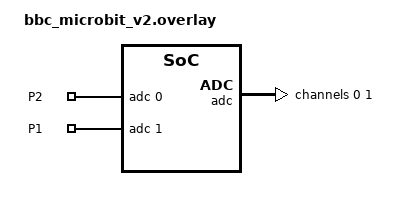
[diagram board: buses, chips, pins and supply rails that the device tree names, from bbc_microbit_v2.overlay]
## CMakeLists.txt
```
cmake_minimum_required(VERSION 3.20.0)
find_package(Zephyr REQUIRED HINTS $ENV{ZEPHYR_BASE})

project(Bit_Player_micro_bit)

target_sources(app PRIVATE 
    src/main.c
    src/joystick_state.c
    src/sender_ble.c
)
```

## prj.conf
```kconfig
# Sender prj.conf - State-based
# Zephyr SDK v2.5.1

CONFIG_SERIAL=y
CONFIG_CONSOLE=y
CONFIG_UART_CONSOLE=y
CONFIG_PRINTK=y

# ADC for joystick
CONFIG_ADC=y
CONFIG_ADC_NRFX_SAADC=y
CONFIG_ADC_ASYNC=y

# GPIO for buttons
CONFIG_GPIO=y

# System
CONFIG_SYSTEM_WORKQUEUE_STACK_SIZE=2048
CONFIG_MAIN_STACK_SIZE=2048
CONFIG_HEAP_MEM_POOL_SIZE=4096

# Bluetooth - Peripheral (sender advertiser)
CONFIG_BT=y
CONFIG_BT_PERIPHERAL=y
CONFIG_BT_DEVICE_NAME="BitPlayer_Joy"
CONFIG_BT_MAX_CONN=1
CONFIG_BT_GATT_DYNAMIC_DB=y

# Buffer
CONFIG_BT_L2CAP_TX_BUF_COUNT=8
CONFIG_BT_L2CAP_TX_MTU=65
CONFIG_BT_BUF_ACL_TX_SIZE=27
CONFIG_BT_BUF_ACL_RX_SIZE=70
```

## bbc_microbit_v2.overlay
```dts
/ {
	zephyr,user {
		io-channels = <&adc 0>, <&adc 1>;
		io-channel-names = "P2", "P1";
	};
};

&adc {
	#address-cells = <1>;
	#size-cells = <0>;
	status = "okay";

	channel@0 {
		reg = <0>;
		zephyr,gain = "ADC_GAIN_1_5";
		zephyr,reference = "ADC_REF_INTERNAL";
		zephyr,acquisition-time = <ADC_ACQ_TIME_DEFAULT>;
		zephyr,input-positive = <2>;  /* AIN2 = P0.04 = P2 edge */
		zephyr,resolution = <10>;
	};

	channel@1 {
		reg = <1>;
		zephyr,gain = "ADC_GAIN_1_5";
		zephyr,reference = "ADC_REF_INTERNAL";
		zephyr,acquisition-time = <ADC_ACQ_TIME_DEFAULT>;
		zephyr,input-positive = <1>;  /* AIN1 = P0.03 = P1 edge */
		zephyr,resolution = <10>;
	};
};
```

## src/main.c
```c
#include <zephyr/kernel.h>
#include <zephyr/device.h>
#include <zephyr/devicetree.h>
#include <zephyr/drivers/adc.h>
#include <zephyr/drivers/gpio.h>
#include <zephyr/sys/printk.h>
#include <nrfx_saadc.h>

#include "joystick_state.h"
#include "sender_ble.h"
#include "motor_types.h"

#define ADC_NODE DT_NODELABEL(adc)
#define RESOLUTION 10 

#define SEND_INTERVAL_MS 100
#define POLL_INTERVAL_MS 20

static const struct gpio_dt_spec btn_a = GPIO_DT_SPEC_GET(DT_ALIAS(sw0), gpios);
static const struct gpio_dt_spec btn_b = GPIO_DT_SPEC_GET(DT_ALIAS(sw1), gpios);

static const struct device *adc_dev;
static int16_t adc_buffer[1];
static int16_t last_x = 512, last_y = 512; 
static int64_t last_send = 0; 

// Configuration for Y axis
static struct adc_channel_cfg cfg_y = {
    .gain = ADC_GAIN_1_5,
    .reference = ADC_REF_INTERNAL,
    .acquisition_time = ADC_ACQ_TIME_DEFAULT,
    .channel_id = 0,
#ifdef CONFIG_ADC_NRFX_SAADC
    .input_positive = NRF_SAADC_INPUT_AIN2,
#endif
};

// Configuration for X axis
static struct adc_channel_cfg cfg_x = {
    .gain = ADC_GAIN_1_5,                   //3,0 V
    .reference = ADC_REF_INTERNAL,
    .acquisition_time = ADC_ACQ_TIME_DEFAULT,
    .channel_id = 1,
#ifdef CONFIG_ADC_NRFX_SAADC
    .input_positive = NRF_SAADC_INPUT_AIN1,
#endif
};

// Read ADC value from specified channel
static int read_adc(int ch, int16_t *val)
{
    struct adc_sequence seq = {
        .buffer = adc_buffer,               // Buffer to store ADC value    
        .buffer_size = sizeof(adc_buffer),  // Buffer size in bytes
        .resolution = RESOLUTION,           // 10-bit resolution
        .channels = BIT(ch),                
    };
    // Perform the ADC read
    int ret = adc_read(adc_dev, &seq);
    if (ret < 0) return ret;
    *val = (adc_buffer[0] < 0) ? 0 : (adc_buffer[0] > 1023) ? 1023 : adc_buffer[0];
    return 0;
}

// Helper to get string name of direction
static const char *dir_name(Motor_direction d)
{
    switch (d) {
        case Forward: return "FWD";
        case Backward: return "BWD";
        case Rotate_Right: return "ROT_R";
        case Rotate_Left: return "ROT_L";
        case Right: return "RIGHT";
        case Left: return "LEFT";
        case Stop: return "STOP";
        case Idle: return "IDLE";
        default: return "?";
    }
}

int main(void)
{
    int16_t y, x;
    Motor_direction dir; // Current direction
    uint8_t speed;

    printk("\n=== Joystick Sender (DEBUG) ===\n");
    printk("Sends Motor_direction directly\n\n");

    if (device_is_ready(btn_a.port)) {
        gpio_pin_configure_dt(&btn_a, GPIO_INPUT | GPIO_PULL_UP); // Configure button A
        gpio_pin_configure_dt(&btn_b, GPIO_INPUT | GPIO_PULL_UP); // Configure button B
    }

    adc_dev = DEVICE_DT_GET(ADC_NODE);
    if (!device_is_ready(adc_dev)) {
        printk("ADC not ready\n");
        return -1;
    }
    adc_channel_setup(adc_dev, &cfg_y);
    adc_channel_setup(adc_dev, &cfg_x);

    joystick_state_init();  // Initialize joystick state
    ble_init();             // Initialize BLE   
    ble_connect();          // Wait until BLE is ready

    printk("Hold A to drive\n\n");

    while (1) {
        // Read joystick
        if (read_adc(cfg_y.channel_id, &y) < 0) y = last_y;
        else last_y = y;

        if (read_adc(cfg_x.channel_id, &x) < 0) x = last_x;
        else last_x = x;

        bool btn = (gpio_pin_get_dt(&btn_a) != 0);
        bool btn_b_state = (gpio_pin_get_dt(&btn_b) != 0);

        // Convert to direction
        bool changed = joystick_to_direction(x, y, btn, btn_b_state, &dir, &speed);

        // DEBUG: Always print raw values 
        printk("X:%4d Y:%4d btn:%d -> %-5s %3d%%", x, y, btn ? 1 : 0, dir_name(dir), speed);

        // Send if changed or interval passed 
        int64_t now = k_uptime_get();
        if (ble_is_ready() && (changed || (now - last_send) >= SEND_INTERVAL_MS)) {
            ble_send_direction(dir, speed);
            last_send = now;
            printk(" [TX]");
        }
        printk("\n");

        k_msleep(POLL_INTERVAL_MS); // Polling interval
    }
    return 0;
}
```

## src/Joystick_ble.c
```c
//Joystick_ble.c - SIMPLIFIED VERSION

#include <zephyr/kernel.h>
#include <zephyr/sys/printk.h>
#include <string.h>

#include <zephyr/bluetooth/bluetooth.h>
#include <zephyr/bluetooth/uuid.h>
#include <zephyr/bluetooth/conn.h>
#include <zephyr/bluetooth/gatt.h>

#include "joystick_ble.h"

#define JOYSTICK_SVC_UUID \
	BT_UUID_128_ENCODE(0x12345678, 0x1234, 0x5678, 0x1234, 0x56789abcdef0)
#define JOYSTICK_CHR_UUID \
	BT_UUID_128_ENCODE(0x12345678, 0x1234, 0x5678, 0x1234, 0x56789abcdef1)

static struct bt_uuid_128 joystick_svc_uuid = BT_UUID_INIT_128(JOYSTICK_SVC_UUID);
static struct bt_uuid_128 joystick_chr_uuid = BT_UUID_INIT_128(JOYSTICK_CHR_UUID);

static const struct bt_data ad[] = {
	BT_DATA_BYTES(BT_DATA_FLAGS, (BT_LE_AD_GENERAL | BT_LE_AD_NO_BREDR)),
	BT_DATA_BYTES(BT_DATA_UUID128_ALL, JOYSTICK_SVC_UUID),
};

static struct bt_conn *default_conn;
static const struct bt_gatt_attr *local_attr;
static bool remote_ready;
static bool is_connected;

/* Joystick data */
struct joystick_data {
	int16_t x_pos;
	int16_t y_pos;
	uint8_t buttons;
} __packed;

/* Send data - enkel versjon */
void ble_send_joystick_data(int16_t x_pos, int16_t y_pos, uint8_t buttons)
{
	if (!default_conn || !remote_ready) return;

	struct joystick_data data = {
		.x_pos = x_pos,
		.y_pos = y_pos,
		.buttons = buttons,
	};

	int err = bt_gatt_notify(default_conn, local_attr, &data, sizeof(data));
	if (err && err != -ENOMEM && err != -ENOTCONN) {
		printk("Notify err %d\n", err);
	}
}

bool ble_is_ready(void)
{
	return (default_conn != NULL && remote_ready);
}

static void joystick_ccc_cfg_changed(const struct bt_gatt_attr *attr, uint16_t val)
{
	remote_ready = (val == BT_GATT_CCC_NOTIFY);
	printk("CCC: %s\n", remote_ready ? "subscribed" : "unsubscribed");
}

BT_GATT_SERVICE_DEFINE(joystick_svc,
	BT_GATT_PRIMARY_SERVICE(&joystick_svc_uuid.uuid),
	BT_GATT_CHARACTERISTIC(&joystick_chr_uuid.uuid, 
	                       BT_GATT_CHRC_NOTIFY,
	                       BT_GATT_PERM_NONE, 
	                       NULL, NULL, NULL),
	BT_GATT_CCC(joystick_ccc_cfg_changed,
	            BT_GATT_PERM_READ | BT_GATT_PERM_WRITE),
);

/* Auto-reconnect work */
static void restart_adv_work(struct k_work *work);
K_WORK_DELAYABLE_DEFINE(adv_work, restart_adv_work);

static void restart_adv_work(struct k_work *work)
{
	if (!is_connected) {
		int err = bt_le_adv_start(BT_LE_ADV_CONN_NAME, ad, ARRAY_SIZE(ad), NULL, 0);
		if (err && err != -EALREADY) {
			printk("Adv retry in 1s\n");
			k_work_schedule(&adv_work, K_SECONDS(1));
		} else {
			printk("Advertising...\n");
		}
	}
}

static void connected(struct bt_conn *conn, uint8_t err)
{
	if (err) {
		printk("Connect failed: 0x%02x\n", err);
		k_work_schedule(&adv_work, K_MSEC(200));
		return;
	}

	printk("Connected\n");
	if (!default_conn) {
		default_conn = bt_conn_ref(conn);
	}
	is_connected = true;
	remote_ready = false;
}

static void disconnected(struct bt_conn *conn, uint8_t reason)
{
	printk("Disconnected: 0x%02x\n", reason);

	if (default_conn) {
		bt_conn_unref(default_conn);
		default_conn = NULL;
	}
	is_connected = false;
	remote_ready = false;

	/* Rask reconnect */
	k_work_schedule(&adv_work, K_MSEC(100));
}

static struct bt_conn_cb conn_callbacks = {
	.connected = connected,
	.disconnected = disconnected,
};

void ble_connect(void)
{
	if (is_connected) return;

	int err = bt_le_adv_start(BT_LE_ADV_CONN_NAME, ad, ARRAY_SIZE(ad), NULL, 0);
	if (err) {
		printk("Adv failed: %d\n", err);
		k_work_schedule(&adv_work, K_MSEC(500));
		return;
	}
	printk("Advertising started\n");
}

void ble_cancel_connect(void)
{
	k_work_cancel_delayable(&adv_work);
	if (is_connected && default_conn) {
		bt_conn_disconnect(default_conn, BT_HCI_ERR_REMOTE_USER_TERM_CONN);
	} else {
		bt_le_adv_stop();
	}
}

void ble_init(void)
{
	int err = bt_enable(NULL);
	if (err) {
		printk("BT init failed: %d\n", err);
		return;
	}
	printk("Bluetooth ready\n");
	bt_conn_cb_register(&conn_callbacks);
	local_attr = &joystick_svc.attrs[1];
}
```

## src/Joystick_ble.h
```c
#ifndef JOYSTICK_BLE_H
#define JOYSTICK_BLE_H

#include <stdbool.h>
#include <stdint.h>

#define BTN_A_MASK (1 << 0)
#define BTN_B_MASK (1 << 1)

void ble_init(void);
void ble_connect(void);
void ble_cancel_connect(void);
void ble_send_joystick_data(int16_t x_pos, int16_t y_pos, uint8_t buttons);
bool ble_is_ready(void);

#endif
```

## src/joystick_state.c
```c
#include "joystick_state.h"

#define JOY_CENTER 512
#define JOY_DEADZONE 60
#define JOY_MAX 1023

static Motor_direction current_dir = Stop;

void joystick_state_init(void) {
	current_dir = Stop;
}

// Convert joystick position and button states to motor direction and speed
bool joystick_to_direction(int16_t x_pos, int16_t y_pos, bool btn_a, bool btn_b, Motor_direction *dir, uint8_t *speed) {

	Motor_direction new_dir = Stop; 
	int8_t new_speed = 0;

	if (!btn_a){
		new_dir = Idle;
		new_speed = 0;
		goto done;
	}

	// Calculate forward/backward and turning components
	int32_t fwd = 0;
	if (y_pos > JOY_CENTER + JOY_DEADZONE) {
		fwd = ((y_pos - JOY_CENTER) * 100) / (JOY_MAX - JOY_CENTER);
	} else if (y_pos < JOY_CENTER - JOY_DEADZONE) {
		fwd = -((JOY_CENTER - y_pos) * 100) / (JOY_CENTER);
	}

	// Calculate turning component
	int32_t turn = 0;
	if (x_pos > JOY_CENTER + JOY_DEADZONE) {
		turn = ((x_pos - JOY_CENTER) * 100) / (JOY_MAX - JOY_CENTER);
	} else if (x_pos < JOY_CENTER - JOY_DEADZONE) {
		turn = -((JOY_CENTER - x_pos) * 100) / (JOY_CENTER);
	}
	
	// Determine direction and speed
	if (fwd == 0 && turn == 0) {
		new_dir = Stop;
		new_speed = 0;
		goto done;
	}

	// Determine speed based on the larger of forward or turning component
    int32_t abs_fwd = (fwd >= 0) ? fwd : -fwd;
    int32_t abs_turn = (turn >= 0) ? turn : -turn;

	new_speed = (abs_fwd > abs_turn) ? abs_fwd : abs_turn;
	if (new_speed > 100) new_speed = 100;

	if(abs_fwd < 25 && abs_turn > 10){
		if (btn_b) {
			// Knapp B: Strafe (sideveis)
			new_dir = (turn > 0) ? Right : Left;
		} else {
			// Normal: Roter på stedet
			new_dir = (turn > 0) ? Rotate_Right : Rotate_Left;
		}
		goto done;
	}

	// Forward/backward with possible slight turn
	if (fwd > 0) {
		if (abs_turn > 50)
			new_dir = (turn > 0) ? Right : Left;
		else {
			new_dir = Forward;
		}
	} else if (fwd < 0) {
		if (abs_turn > 50)
			new_dir = (turn > 0) ? Right : Left;
		else {
			new_dir = Backward;
		}
	} else {
		if (abs_turn > 10) {
            new_dir = (turn > 0) ? Rotate_Right : Rotate_Left;
        }
	}

done:
 *dir = new_dir;
 *speed = new_speed;

 bool changed = (new_dir != current_dir);
 current_dir = new_dir;
 return changed;
}
```

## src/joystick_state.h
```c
#ifndef JOYSTICK_STATE_H
#define JOYSTICK_STATE_H

#include "motor_types.h"
#include <stdbool.h>

void joystick_state_init(void);

bool joystick_to_direction(int16_t x_pos, int16_t y_pos, bool btn_a_pressed, bool btn_b_pressed, Motor_direction *dir, uint8_t *speed);

#endif
```

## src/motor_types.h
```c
/*
* Acknowledgement:
* This file includes example code derrived from https://github.com/OskeLTU
* Driving_car motor_controls.h
*/

#ifndef MOTOR_TYPES_H
#define MOTOR_TYPES_H
#include <stdint.h>
typedef enum {
    Forward,
    Backward,
    Rotate_Right,
    Rotate_Left,
    Right,
    Left,
    Stop,
    Idle
} Motor_direction;

struct drive_packet {
    uint8_t direction;  // Motor_direction
    uint8_t speed;      // Speed value 0-100%
} __packed;
 #endif // MOTOR_TYPES_H
```

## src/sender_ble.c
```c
/*
* Acknowledgement:
* This file includes example code derrived from the Zephyr Project 
* Pong sample
*/
#include <zephyr/kernel.h>
#include <zephyr/sys/printk.h>
#include <zephyr/bluetooth/bluetooth.h>
#include <zephyr/bluetooth/uuid.h>
#include <zephyr/bluetooth/conn.h>
#include <zephyr/bluetooth/gatt.h>

#include "sender_ble.h"
#include "motor_types.h"

// UUIDs for the Drive Service and Characteristic
#define DRIVE_SVC_UUID \
    BT_UUID_128_ENCODE(0x12345678, 0x1234, 0x5678, 0x1234, 0x56789abcdef0)

// Characteristic UUID
#define DRIVE_CHR_UUID \
    BT_UUID_128_ENCODE(0x12345678, 0x1234, 0x5678, 0x1234, 0x56789abcdef1)

static struct bt_uuid_128 svc_uuid = BT_UUID_INIT_128(DRIVE_SVC_UUID); // Service UUID
static struct bt_uuid_128 chr_uuid = BT_UUID_INIT_128(DRIVE_CHR_UUID); // Characteristic UUID

// Advertising data
static const struct bt_data ad[] = {
    BT_DATA_BYTES(BT_DATA_FLAGS, (BT_LE_AD_GENERAL | BT_LE_AD_NO_BREDR)),
    BT_DATA_BYTES(BT_DATA_UUID128_ALL, DRIVE_SVC_UUID),
};

// Connection state
static struct bt_conn *conn;                    // Current connection
static const struct bt_gatt_attr *notify_attr;  // Notify characteristic attribute
static bool subscribed;                         // Is client subscribed to notifications
static bool connected;                          // Is device connected

// GATT characteristic write callback
void ble_send_direction(Motor_direction dir, uint8_t speed) {
    if (!connected || !subscribed) {
        return;
    }

    struct drive_packet packet = {
        .direction = (uint8_t)dir,
        .speed = speed
    };

    bt_gatt_notify(conn, notify_attr, &packet, sizeof(packet));
}

// Bluetooth connection callbacks
bool ble_is_ready(void) {
    return (conn != NULL && subscribed);
}

// Bluetooth connection callbacks
static void ccc_changed(const struct bt_gatt_attr *attr, uint16_t val)
{
    subscribed = (val == BT_GATT_CCC_NOTIFY);
    printk("Subscribed: %s\n", subscribed ? "yes" : "no");
}

// GATT service definition
BT_GATT_SERVICE_DEFINE(drive_svc,
    BT_GATT_PRIMARY_SERVICE(&svc_uuid.uuid),
    BT_GATT_CHARACTERISTIC(&chr_uuid.uuid,
                           BT_GATT_CHRC_NOTIFY,
                           BT_GATT_PERM_NONE,
                           NULL, NULL, NULL),
    BT_GATT_CCC(ccc_changed, BT_GATT_PERM_READ | BT_GATT_PERM_WRITE),
);

// Reconnection work item
static void reconnect_work_fn(struct k_work *work);
K_WORK_DELAYABLE_DEFINE(reconnect_work, reconnect_work_fn);

static void reconnect_work_fn(struct k_work *work)
{
    if (!connected) {
        int err = bt_le_adv_start(BT_LE_ADV_CONN_NAME, ad, ARRAY_SIZE(ad), NULL, 0);
        if (err && err != -EALREADY) {
            k_work_schedule(&reconnect_work, K_SECONDS(1));
        }
    }
}

// Connection callbacks
static void on_connected(struct bt_conn *c, uint8_t err)
{
    if (err) {
        printk("Connect failed: %d\n", err);
        k_work_schedule(&reconnect_work, K_MSEC(200));
        return;
    }
    printk("Connected\n");
    conn = bt_conn_ref(c);
    connected = true;
    subscribed = false;
}


// Disconnection callback
static void on_disconnected(struct bt_conn *c, uint8_t reason)
{
    printk("Disconnected: 0x%02x\n", reason);
    if (conn) {
        bt_conn_unref(conn);
        conn = NULL;
    }
    connected = false;
    subscribed = false;
    k_work_schedule(&reconnect_work, K_MSEC(100));
}

/* Connection callbacks */
static struct bt_conn_cb conn_cb = {
    .connected = on_connected,
    .disconnected = on_disconnected,
};

void ble_connect(void)
{
    if (connected) return;
    int err = bt_le_adv_start(BT_LE_ADV_CONN_NAME, ad, ARRAY_SIZE(ad), NULL, 0);
    if (err) {
        printk("Adv failed: %d\n", err);
        k_work_schedule(&reconnect_work, K_MSEC(500));
    } else {
        printk("Advertising...\n");
    }
}

void ble_init(void)
{
    int err = bt_enable(NULL);
    if (err) {
        printk("BT init failed: %d\n", err);
        return;
    }
    printk("Bluetooth ready\n");
    bt_conn_cb_register(&conn_cb);
    notify_attr = &drive_svc.attrs[1];
}
```

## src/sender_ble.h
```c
/*
* Acknowledgement:
* This file includes example code derrived from the Zephyr Project 
* Pong sample
*/
#ifndef SENDER_BLE_H
#define SENDER_BLE_H

#include "motor_types.h"
#include <stdbool.h>
#include <stdint.h>

void ble_init(void);
void ble_connect(void);
void ble_send_direction(Motor_direction dir, uint8_t speed);
bool ble_is_ready(void);

#endif
```
